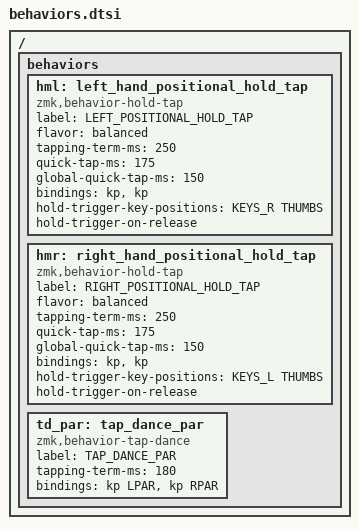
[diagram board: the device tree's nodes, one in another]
#define KEYS_L LT0 LT1 LT2 LT3 LT4 LM0 LM1 LM2 LM3 LM4 LB0 LB1 LB2 LB3 LB4  // left hand
#define KEYS_R RT0 RT1 RT2 RT3 RT4 RM0 RM1 RM2 RM3 RM4 RB0 RB1 RB2 RB3 RB4  // right hand
#define THUMBS LH1 LH0 RH0 RH1

/ {
  behaviors {
    hml: left_hand_positional_hold_tap {
      compatible = "zmk,behavior-hold-tap";
      label = "LEFT_POSITIONAL_HOLD_TAP";
      #binding-cells = <2>;
      flavor = "balanced";
      tapping-term-ms = <250>;            // <---[[produces tap if held longer than tapping-term-ms]]
      quick-tap-ms = <175>;
      global-quick-tap-ms = <150>;        // requires PR #1387
      bindings = <&kp>, <&kp>;
      hold-trigger-key-positions = <KEYS_R THUMBS>;    // <---[[right-hand keys]]
      hold-trigger-on-release;            // requires PR #1423
    }; 

    hmr: right_hand_positional_hold_tap {
      compatible = "zmk,behavior-hold-tap";
      label = "RIGHT_POSITIONAL_HOLD_TAP";
      #binding-cells = <2>;
      flavor = "balanced";
      tapping-term-ms = <250>;            // <---[[produces tap if held longer than tapping-term-ms]]
      quick-tap-ms = <175>;
      global-quick-tap-ms = <150>;        // requires PR #1387
      bindings = <&kp>, <&kp>;
      hold-trigger-key-positions = <KEYS_L THUMBS>;    // <---[[left-hand keys]]
      hold-trigger-on-release;            // requires PR #1423
    }; 

    td_par: tap_dance_par {
      compatible = "zmk,behavior-tap-dance";
      label = "TAP_DANCE_PAR";
      #binding-cells = <0>;
      tapping-term-ms = <180>;
      bindings = <&kp LPAR>, <&kp RPAR>;
    };
  };
};
